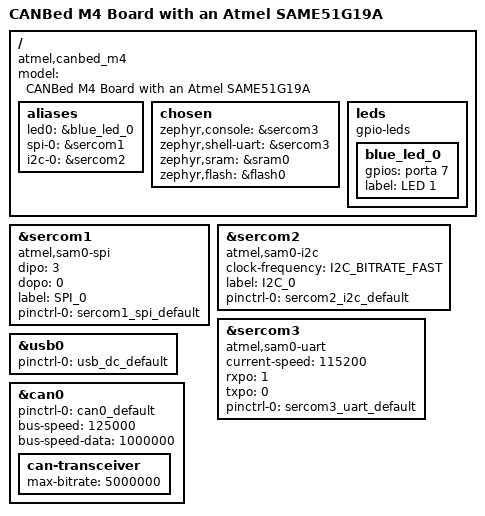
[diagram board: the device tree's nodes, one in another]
/*
 * Copyright (c) 2022 Slawomir Ciesielski <slawomir.ciesielski@anyware.dev>
 * SPDX-License-Identifier: Apache-2.0
 */

/dts-v1/;

#include <atmel/same5xx19.dtsi>
#include "canbed_m4-pinctrl.dtsi"

/ {
	model = "CANBed M4 Board with an Atmel SAME51G19A";
	compatible = "atmel,canbed_m4", "atmel,same51g19a", "atmel,same54";

	aliases {
		led0 = &blue_led_0;
		spi-0 = &sercom1;
		i2c-0 = &sercom2;
	};

	chosen {
		zephyr,console = &sercom3;
		zephyr,shell-uart = &sercom3;
		zephyr,sram = &sram0;
		zephyr,flash = &flash0;
	};

	leds {
		compatible = "gpio-leds";
		blue_led_0: blue_led_0 {
			gpios = <&porta 7 GPIO_ACTIVE_HIGH>;
			label = "LED 1";
		};
	};

	// gpio_keys {
	// 	compatible = "gpio-keys";
	// 	user_button: button_1 {
	// 		label = "User Button";
	// 		gpios = <&pioa 5 (GPIO_PULL_UP | GPIO_ACTIVE_LOW)>;
	// 	};
	// };

	// xplained1_header: xplained-connector1 {
	// 	compatible = "atmel-xplained-header";
	// 	#gpio-cells = <2>;
	// 	gpio-map-mask = <0xffffffff 0xffffffc0>;
	// 	gpio-map-pass-thru = <0 0x3f>;		/*           Shared */
	// 	gpio-map =	<0 0 &pioa  3 0>,	/* TWD0           y */
	// 			<1 0 &pioa  4 0>,	/* TWCK0          y */
	// 			<2 0 &piob  2 0>,	/* URXD1            */
	// 			<3 0 &piob  3 0>,	/* UTXD1            */
	// 			<4 0 &pioa 31 0>,	/* SPI(CS)          */
	// 			<5 0 &pioa 13 0>,	/* SPI(MOSI)      y */
	// 			<6 0 &pioa 12 0>,	/* SPI(MISO)      y */
	// 			<7 0 &pioa 14 0>;	/* SPI(SCK)       y */
	// 						/* GND              */
	// 						/* +3.3V            */
	// };

	// xplained2_header: xplained-connector2 {
	// 	compatible = "atmel-xplained-header";
	// 	#gpio-cells = <2>;
	// 	gpio-map-mask = <0xffffffff 0xffffffc0>;
	// 	gpio-map-pass-thru = <0 0x3f>;		/*           Shared */
	// 	gpio-map =	<0 0 &pioa 22 0>,	/* GPIO             */
	// 			<1 0 &pioc 12 0>,	/* GPIO             */
	// 			<2 0 &piob  0 0>,	/* GPIO             */
	// 			<3 0 &piob  1 0>,	/* GPIO             */
	// 			<4 0 &pioa 17 0>,	/* GPIO             */
	// 			<5 0 &pioa 21 0>,	/* GPIO             */
	// 			<6 0 &pioc 13 0>,	/* GPIO             */
	// 			<7 0 &pioc 15 0>;	/* GPIO             */
	// 						/* GND              */
	// 						/* +3.3V            */
	// };

	// xplained3_header: xplained-connector3 {
	// 	compatible = "atmel-xplained-header";
	// 	#gpio-cells = <2>;
	// 	gpio-map-mask = <0xffffffff 0xffffffc0>;
	// 	gpio-map-pass-thru = <0 0x3f>;		/*           Shared */
	// 	gpio-map =	<0 0 &pioa 20 0>,	/* GPIO             */
	// 			<1 0 &pioa 11 0>,	/* GPIO             */
	// 			<2 0 &pioa 23 0>,	/* GPIO             */
	// 			<3 0 &pioa 18 0>,	/* GPIO             */
	// 			<4 0 &pioa 15 0>,	/* GPIO             */
	// 			<5 0 &pioa 16 0>,	/* GPIO             */
	// 			<6 0 &pioa  2 0>,	/* GPIO             */
	// 			<7 0 &pioc  2 0>;	/* GPIO             */
	// 						/* GND              */
	// 						/* +3.3V            */
	// };

	// xplained4_header: xplained-connector4 {
	// 	compatible = "atmel-xplained-header";
	// 	#gpio-cells = <2>;
	// 	gpio-map-mask = <0xffffffff 0xffffffc0>;
	// 	gpio-map-pass-thru = <0 0x3f>;		/*           Shared */
	// 	gpio-map =	<0 0 &pioa  3 0>,	/* TWD0           y */
	// 			<1 0 &pioa  4 0>,	/* TWCK0          y */
	// 			<2 0 &piob  2 0>,	/* URXD1            */
	// 			<3 0 &piob  3 0>,	/* UTXD1            */
	// 			<4 0 &pioa 30 0>,	/* SPI(CS)          */
	// 			<5 0 &pioa 13 0>,	/* SPI(MOSI)      y */
	// 			<6 0 &pioa 12 0>,	/* SPI(MISO)      y */
	// 			<7 0 &pioa 14 0>;	/* SPI(SCK)       y */
	// 						/* GND              */
	// 						/* +3.3V            */
	// };
};

&sercom1 {
	status = "okay";
	compatible = "atmel,sam0-spi";
	dipo = <3>;
	dopo = <0>;
	label = "SPI_0";
	#address-cells = <1>;
	#size-cells = <0>;

	pinctrl-0 = <&sercom1_spi_default>;
	pinctrl-names = "default";
};

&sercom2 {
	status = "okay";
	compatible = "atmel,sam0-i2c";
	clock-frequency = <I2C_BITRATE_FAST>;
	label = "I2C_0";
	#address-cells = <1>;
	#size-cells = <0>;

	pinctrl-0 = <&sercom2_i2c_default>;
	pinctrl-names = "default";
};

&sercom3 {
	status = "okay";
	compatible = "atmel,sam0-uart";
	current-speed = <115200>;
	rxpo = <1>;
	txpo = <0>;
	#address-cells = <1>;
	#size-cells = <0>;

	pinctrl-0 = <&sercom3_uart_default>;
	pinctrl-names = "default";
};

zephyr_udc0: &usb0 {
	status = "okay";

	pinctrl-0 = <&usb_dc_default>;
	pinctrl-names = "default";
};

&can0 {
	status = "okay";

	pinctrl-0 = <&can0_default>;
	pinctrl-names = "default";

	bus-speed = <125000>;
	bus-speed-data = <1000000>;

	can-transceiver {
		max-bitrate = <5000000>;
	};
};
